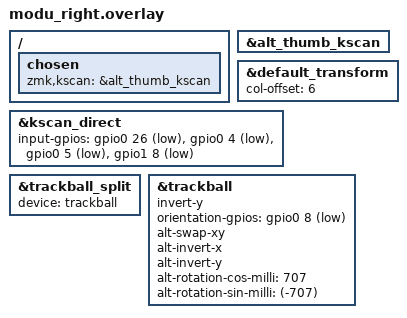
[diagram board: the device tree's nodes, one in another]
/*
 * Copyright (c) 2026 EKS Inc.
 * Created by Ryu.
 * SPDX-License-Identifier: LicenseRef-EKS-NonCommercial-1.0
 *
 * BLE wireless peripheral. Forwards its trackball to central via input-split.
 */

#include "modu.dtsi"

/ {
    chosen {
        zmk,kscan = &alt_thumb_kscan;
    };
};

&alt_thumb_kscan {
    status = "okay";
};

&default_transform {
    col-offset = <6>;
};

&kscan_direct {
    input-gpios
        = <&gpio0 26 (GPIO_ACTIVE_LOW | GPIO_PULL_UP)>
        , <&gpio0  4 (GPIO_ACTIVE_LOW | GPIO_PULL_UP)>
        , <&gpio0  5 (GPIO_ACTIVE_LOW | GPIO_PULL_UP)>
        , <&gpio1  8 (GPIO_ACTIVE_LOW | GPIO_PULL_UP)>
        ;
};

&trackball_split {
    device = <&trackball>;
};

&trackball {
    invert-y;
    orientation-gpios = <&gpio0 8 (GPIO_ACTIVE_LOW | GPIO_PULL_UP)>;
    alt-swap-xy;
    alt-invert-x;
    alt-invert-y;
    alt-rotation-cos-milli = <707>;
    alt-rotation-sin-milli = <(-707)>;
};
